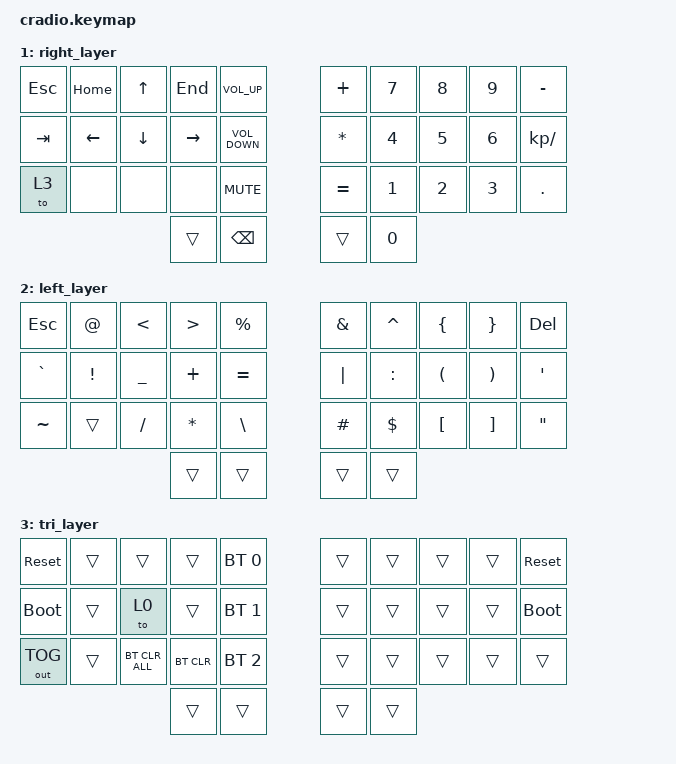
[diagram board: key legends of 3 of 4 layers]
// Copyright (c) 2022 The ZMK Contributors
// SPDX-License-Identifier: MIT

#include <behaviors.dtsi>
#include <dt-bindings/zmk/keys.h>
#include <dt-bindings/zmk/bt.h>
#include <dt-bindings/zmk/outputs.h>

// Home row mods macro
#define HRML(k1,k2) &ht LCTRL k1  &ht LSHFT k2
#define HRMR(k1,k2) &ht RSHFT k1  &ht RCTRL k2

&mt {
   flavor = "tap-preferred";
   tapping_term_ms = <180>;
};

/ {
    // macros
    macros {
    ZMK_MACRO(name1,
        wait-ms = <0>;
        tap-ms  = <10>;
        bindings = <&kp U &kp F &kp A &kp N>
                 , <&kp N2 &kp N1 &kp N2 &kp N9>
                 , <&kp UNDERSCORE>
                 , <&kp Z &kp H &kp O &kp U &kp Y &kp O &kp N &kp G>;
    )

    ZMK_MACRO(name2,
        wait-ms = <0>;
        tap-ms  = <10>;
        bindings = <&kp LS(W) &kp N0>
                 , <&kp LS(L) &kp N0 &kp V &kp E>
                 , <&kp LS(Z) &kp I>
                 , <&kp LS(Y) &kp N0 &kp U &kp EXCL>
                 , <&kp UNDERSCORE>
                 , <&kp N0 &kp N5 &kp N3 &kp N2>;
    )

    ZMK_MACRO(spc1,
        wait-ms = <0>;
        tap-ms  = <10>;
        bindings = <&kp LA(M) &kp N1>;
    )

    ZMK_MACRO(spc2,
        wait-ms = <0>;
        tap-ms  = <10>;
        bindings = <&kp LA(M) &kp N2>;
    )

    ZMK_MACRO(spc3,
        wait-ms = <0>;
        tap-ms  = <10>;
        bindings = <&kp LA(M) &kp N3>;
    )

    ZMK_MACRO(spc4,
        wait-ms = <0>;
        tap-ms  = <10>;
        bindings = <&kp LA(M) &kp N4>;
    )

    ZMK_MACRO(nxt_tab,
        wait-ms = <0>;
        tap-ms  = <10>;
        bindings = <&kp LC(TAB)>;
    )

    ZMK_MACRO(prv_tab,
        wait-ms = <0>;
        tap-ms  = <10>;
        bindings = <&kp LC(LS(TAB))>;
    )
    };

    behaviors {
        ht: hold_tap {
            label = "hold_tap";
            compatible = "zmk,behavior-hold-tap";
            #binding-cells = <2>;
            flavor = "tap-preferred";
            tapping-term-ms = <180>;
            quick-tap-ms = <150>;
            global-quick-tap;
            bindings = <&kp>, <&kp>;
        };
    };


    // combos
    combos {
      compatible = "zmk,combos";
      // right hand
      combo_esc {
          timeout-ms = <50>;
          key-positions = <16 17>;
          bindings = <&kp ESC>;
      };

      combo_lgui {
          timeout-ms = <50>;
          key-positions = <5 6>;
          bindings = <&kp LGUI>;
      };

      combo_fullscreen {
          timeout-ms = <50>;
          key-positions = <25 26>;
          bindings = <&kp F11>;
      };

      combo_wkspc_up {
          timeout-ms = <50>;
          key-positions = <9 19>;
          bindings = <&kp LC(UP)>;
      };

      combo_wkspc_down {
          timeout-ms = <50>;
          key-positions = <19 29>;
          bindings = <&kp LC(DOWN)>;
      };

      combo_win_up {
          timeout-ms = <50>;
          key-positions = <7 8>;
          bindings = <&kp LS(LG(UP))>;
      };

      combo_win_down {
          timeout-ms = <50>;
          key-positions = <27 28>;
          bindings = <&kp LS(LG(DOWN))>;
      };

      combo_win_left {
          timeout-ms = <50>;
          key-positions = <17 18>;
          bindings = <&kp LS(LG(LEFT))>;
      };

      combo_win_right {
          timeout-ms = <50>;
          key-positions = <9 18>;
          bindings = <&kp LS(LG(RIGHT))>;
      };

      combo_rdelete {
          timeout-ms = <50>;
          key-positions = <15 16>;
          bindings = <&kp DELETE>;
      };

      // left hand
      combo_zoomin {
          timeout-ms = <50>;
          key-positions = <3 4>;
          bindings = <&kp LC(PLUS)>;
      };

      combo_zoomout {
          timeout-ms = <50>;
          key-positions = <23 24>;
          bindings = <&kp LC(MINUS)>;
      };

      combo_pgdn {
          timeout-ms = <50>;
          key-positions = <22 23>;
          bindings = <&kp PG_DN>;
      };

      combo_pgup {
          timeout-ms = <50>;
          key-positions = <2 3>;
          bindings = <&kp PG_UP>;
      };

      combo_ldelete {
          timeout-ms = <50>;
          key-positions = <13 14>;
          bindings = <&kp DELETE>;
      };

      // symbols
      combo_underscore {
          timeout-ms = <50>;
          key-positions = <11 12>;
          bindings = <&kp UNDERSCORE>;
      };

      combo_minus {
          timeout-ms = <50>;
          key-positions = <12 13>;
          bindings = <&kp MINUS>;
      };

      // others
      combo_capswd {
          timeout-ms = <50>;
          key-positions = <2 7>;
          bindings = <&caps_word>;
      };

    };

    // conditional_layers {
    //     compatible = "zmk,conditional-layers";
    //     tri_layer {
    //         if-layers = <1 2>;
    //         then-layer = <3>;
    //     };
    // };

    keymap {
        compatible = "zmk,keymap";
        default_layer {
            bindings = <
        //╭──────────┬──────────┬──────────┬──────────┬──────────╮   ╭──────────┬──────────┬──────────┬──────────┬──────────╮
        //│  Q       │  W       │  F       │  P       │  B       │   │  J       │  L       │  U       │  Y       │  ;       │
            &kp Q      &kp W      &kp F      &kp P      &kp B          &kp J      &kp L      &kp U      &kp Y      &kp SEMI
        //├──────────┼──────────┼──────────┼──────────┼──────────┤   ├──────────┼──────────┼──────────┼──────────┼──────────┤
        //│  A       │  R       │  S       │  T       │  G       │   │  M       │  N       │  E       │  I       │  O       │
            HRML(A,        R)     &lt 2 S    &lt 1 T    &kp G          &kp M      &lt 1 N    &lt 2 E     HRMR(I,        O)
        //├──────────┼──────────┼──────────┼──────────┼──────────┤   ├──────────┼──────────┼──────────┼──────────┼──────────┤
        //│  Z       │  X       │  C       │  D       │  V       │   │  K       │  H       │ , <      │ . >      │ / ?      │
            &kp Z      &kp X      &kp C      &kp D      &kp V          &kp K      &kp H      &kp COMMA  &kp DOT    &kp FSLH
        //╰──────────┴──────────┴──────────┼──────────┼──────────┤   ├──────────┼──────────┼──────────┴──────────┴──────────╯
                                            &kp LGUI   &mt LALT BSPC   &mt RGUI RET  &mt RALT SPACE
        //                                 ╰──────────┴──────────╯   ╰──────────┴──────────╯
            >;
        };

        right_layer {
            bindings = <
        //╭──────────┬──────────┬──────────┬──────────┬──────────╮   ╭──────────┬──────────┬──────────┬──────────┬──────────╮
        //│ ESC      │ HOME     │  UP      │  END     │ V UP     │   │  +       │  7       │  8       │  9       │  -       │
            &kp ESC    &kp HOME    &kp UP     &kp END   &kp C_VOLUME_UP   &kp PLUS   &kp N7     &kp N8     &kp N9     &kp MINUS 
        //├──────────┼──────────┼──────────┼──────────┼──────────┤   ├──────────┼──────────┼──────────┼──────────┼──────────┤
        //│ TAP      │  LEFT    │  DOWN    │  RIGHT   │ V DOWN   │   │  *       │  4       │  5       │  6       │  /       │
            &kp TAB    &kp LEFT   &kp DOWN   &kp RIGHT  &kp C_VOLUME_DOWN  &kp ASTRK  &kp N4     &kp N5     &kp N6    &kp KP_DIVIDE
        //├──────────┼──────────┼──────────┼──────────┼──────────┤   ├──────────┼──────────┼──────────┼──────────┼──────────┤
        //│ Layer 3  │          |          │          │ V MUTE   │   │  =       │  1       │  2       │  3       │          │
            &to 3      &none      &none      &none      &kp C_MUTE      &kp EQUAL  &kp N1     &kp N2     &kp N3     &kp DOT
        //╰──────────┴──────────┴──────────┼──────────┼──────────┤   ├──────────┼──────────┼──────────┴──────────┴──────────╯
        //                                 │          │          │   │          │  0       │ 
                                             &trans     &kp BSPC       &trans      &kp N0
        //                                 ╰──────────┴──────────╯   ╰──────────┴──────────╯
            >;
        };

        left_layer {
            bindings = <
        //╭──────────┬──────────┬──────────┬──────────┬──────────╮   ╭──────────┬──────────┬──────────┬──────────┬──────────╮
        //│  ESC     │  @       │  <       │  >       │  %       │   │  &       │  ^       │  {       │  }       │          │
            &kp ESC    &kp AT     &kp LT     &kp GT     &kp PRCNT       &kp AMPS   &kp CARET  &kp LBRC   &kp RBRC   &kp DEL 
        //├──────────┼──────────┼──────────┼──────────┼──────────┤   ├──────────┼──────────┼──────────┼──────────┼──────────┤
        //│  `       │  !       │  _       │  +       │  =       │   │  *       │  :       │  (       │  )       │  '       │
           &kp GRAVE   &kp EXCL   &kp UNDER  &kp PLUS   &kp EQUAL      &kp PIPE   &kp COLON  &kp LPAR   &kp RPAR   &kp SQT 
        //├──────────┼──────────┼──────────┼──────────┼──────────┤   ├──────────┼──────────┼──────────┼──────────┼──────────┤
        //│  ~       │          │  /       │  *       │  \       │   │  &       │  $       │  [       │  ]       │  "       │
            &kp TILDE  &trans     &kp SLASH  &kp STAR   &kp BSLH       &kp HASH   &kp DLLR  &kp LBKT    &kp RBKT   &kp DQT
        //╰──────────┴──────────┴──────────┼──────────┼──────────┤   ├──────────┼──────────┼──────────┴──────────┴──────────╯
                                             &trans     &trans         &trans     &trans
        //                                 ╰──────────┴──────────╯   ╰──────────┴──────────╯
            >;
        };

        tri_layer {
            bindings = <
        //╭──────────┬──────────┬──────────┬──────────┬──────────╮   ╭──────────┬──────────┬──────────┬──────────┬──────────╮
        //│ RESET    │          │          │          │PROFILE 0 │   │          │          │          │          │  RESET   │
           &sys_reset  &trans     &trans     &trans    &bt BT_SEL 0    &trans     &trans     &trans     &trans    &sys_reset
        //├──────────┼──────────┼──────────┼──────────┼──────────┤   ├──────────┼──────────┼──────────┼──────────┼──────────┤
        //│BOOTLOADER│          │          │          │PROFILE 1 │   │          │          │          │          │BOOTLOADER│
          &bootloader  &trans     &to 0      &trans    &bt BT_SEL 1    &trans     &trans     &trans     &trans    &bootloader
        //├──────────┼──────────┼──────────┼──────────┼──────────┤   ├──────────┼──────────┼──────────┼──────────┼──────────┤
        //│          │          │BT_CLR_ALL│ CLEAR BT │PROFILE 2 │   │          │          │          │          │          │
          &out OUT_TOG &trans   &bt BT_CLR_ALL &bt BT_CLR &bt BT_SEL 2    &trans     &trans     &trans     &trans     &trans
        //╰──────────┴──────────┴──────────┼──────────┼──────────┤   ├──────────┼──────────┼──────────┴──────────┴──────────╯
                                             &trans     &trans         &trans     &trans
        //                                 ╰──────────┴──────────╯   ╰──────────┴──────────╯
            >;
        };
    };
};
